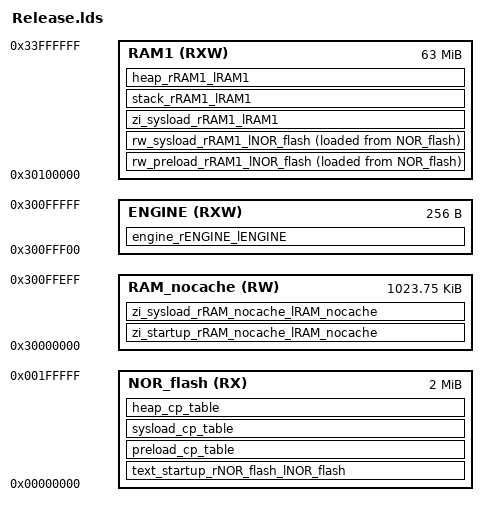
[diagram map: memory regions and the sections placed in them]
/* ld Linker Script - (Debug/Release) */
/* Auto generated by DJYOS lds Editor */
/* Mon Oct 22 22:37:40 CST 2012 */

MEMORY
{
	NOR_flash(RX)		: org = 0, len = 2M
	RAM_nocache(RW)		: org = 0x30000000, len = 0xfff00
	ENGINE(RXW)		: org = 0x300fff00, len = 0x100
	RAM1(RXW)		: org = 0x30100000, len = 63M
}

SECTIONS
{
	
	. = ALIGN(0x08);
	text_startup_rNOR_flash_lNOR_flash :
	{
		KEEP(* (.isr_vector .isr_vector.*))
		./src/bsp/arch/s3c2440/startup/*.o (.text .text.* .rodata .rodata.*)
		./src/bsp/arch/s3c2440/core/*.o (.text .text.* .rodata .rodata.*)
		./src/bsp/arch/arm_common/*.o (.text .text.* .rodata .rodata.*)
		./src/loader/si/pre_loader.o (.text .text.* .rodata .rodata.*)
	}>NOR_flash 
	
	. = ALIGN(0x08);
	zi_startup_rRAM_nocache_lRAM_nocache (NOLOAD) :
	{
		./src/bsp/arch/arm_common/mmucache.o (.mmutable)
	}>RAM_nocache 
	
	. = ALIGN(0x08);
	rw_preload_rRAM1_lNOR_flash :
	{
		KEEP(* (.table.exceptions .table.exceptions.*))
		KEEP(* (.table.vectors .table.vectors.*))
		./src/loader/si/loader.o (.text .text.* .rodata .rodata.*)
		./src/bsp/arch/s3c2440/core/*.o (.text .text.* .rodata .rodata.*)
		./src/djyos/int/int.o (.text .text.* .rodata .rodata.*)
		./src/user/critical/*.o (.text .text.* .rodata .rodata.*)
		./src/bsp/cpu_peripheral/src/gpio.o (.text .text.* .rodata .rodata.*)
		./src/bsp/cpu_peripheral/src/cpu_peri.o (.text .text.* .rodata .rodata.*)
		./src/loader/si/loader.o (.data .data.*)
		./src/bsp/arch/s3c2440/core/*.o  (.data .data.*)
		./src/djyos/int/int.o (.data .data.*)
		./src/user/critical/*.o (.data .data.*)
		./src/bsp/cpu_peripheral/src/gpio.o (.data .data.*)
		./src/bsp/cpu_peripheral/src/cpu_peri.o (.data .data.*)
		./src/loader/si/loader.o (.bss .bss.* COMMON)
		./src/bsp/arch/s3c2440/core/*.o (.bss .bss.* COMMON)
		./src/djyos/int/int.o (.bss .bss.* COMMON)
		./src/user/critical/*.o (.bss .bss.* COMMON)
		./src/bsp/cpu_peripheral/src/gpio.o (.bss .bss.* COMMON)
		./src/bsp/cpu_peripheral/src/cpu_peri.o (.bss .bss.* COMMON)
	}>RAM1 AT>NOR_flash
	
	. = ALIGN(0x08);
	rw_sysload_rRAM1_lNOR_flash :
	{
		* (.text .text.* .rodata .rodata.*)
		* (.data .data.*)
	}>RAM1 AT>NOR_flash
	
	. = ALIGN(0x08);
	zi_sysload_rRAM_nocache_lRAM_nocache (NOLOAD) :
	{
		./src/bsp/board_peripheral/lcd/lcddrv.o(.bss.u8g_video_buffer)
	}>RAM_nocache 
	
	. = ALIGN(0x08);
	zi_sysload_rRAM1_lRAM1 (NOLOAD) :
	{
		* (.bss .bss.* COMMON)
	}>RAM1 
	
	. = ALIGN(0x08);
	preload_cp_table :
	{
		preload_copy_table = .;
		LONG(16)
		LONG(1)
		
		LONG(LOADADDR(rw_preload_rRAM1_lNOR_flash))
		LONG(ADDR(rw_preload_rRAM1_lNOR_flash))
		LONG(SIZEOF(rw_preload_rRAM1_lNOR_flash))
		LONG(1)
	}>NOR_flash 
	
	. = ALIGN(0x08);
	sysload_cp_table :
	{
		sysload_copy_table = .;
		LONG(16)
		LONG(3)
		
		LONG(LOADADDR(rw_sysload_rRAM1_lNOR_flash))
		LONG(ADDR(rw_sysload_rRAM1_lNOR_flash))
		LONG(SIZEOF(rw_sysload_rRAM1_lNOR_flash))
		LONG(1)
		
		LONG(LOADADDR(zi_sysload_rRAM_nocache_lRAM_nocache))
		LONG(ADDR(zi_sysload_rRAM_nocache_lRAM_nocache))
		LONG(SIZEOF(zi_sysload_rRAM_nocache_lRAM_nocache))
		LONG(0)
		
		LONG(LOADADDR(zi_sysload_rRAM1_lRAM1))
		LONG(ADDR(zi_sysload_rRAM1_lRAM1))
		LONG(SIZEOF(zi_sysload_rRAM1_lRAM1))
		LONG(0)
	}>NOR_flash 
	
	. = ALIGN(0x08);
	stack_rRAM1_lRAM1 (NOLOAD) :
	{
		usr_bottom = .;
		KEEP(* (.stack.usr .stack.usr.*))
		usr_top = ALIGN(0x08);
		
		svc_bottom = .;
		KEEP(* (.stack.svc .stack.svc.*))
		svc_top = ALIGN(0x08);
		
		irq_bottom = .;
		KEEP(* (.stack.irq .stack.irq.*))
		irq_top = ALIGN(0x08);
		
		fiq_bottom = .;
		KEEP(* (.stack.fiq .stack.fiq.*))
		fiq_top = ALIGN(0x08);
		
		undef_bottom = .;
		KEEP(* (.stack.undef .stack.undef.*))
		undef_top = ALIGN(0x08);
		
		abort_bottom = .;
		KEEP(* (.stack.abort .stack.abort.*))
		abort_top = ALIGN(0x08);
		
	}>RAM1 
	
	. = ALIGN(0x08);
	heap_rRAM1_lRAM1 (NOLOAD) :
	{
		sys_heap_bottom = .;
	}>RAM1 
	sys_heap_top = 0x30100000+63M;
	
	. = ALIGN(0x08);
	heap_cp_table :
	{
		heap_copy_table = .;
		LONG(12)
		LONG(1)
		
		sys_heap_bottom_cnt = .;
		LONG(sys_heap_bottom)
		sys_heap_top_cnt = .;
		LONG(sys_heap_top)
	}>NOR_flash 
	
	. = ALIGN(0x08);
	engine_rENGINE_lENGINE (NOLOAD) :
	{
		engine_irq = .;
		. += 0x04;
		engine_fiq = .;
		. += 0x04;
		engine_undef = .;
		. += 0x04;
		engine_swi = .;
		. += 0x04;
		engine_pabort = .;
		. += 0x04;
		engine_dabort = .;
		. += 0x04;
		engine_reserved = .;
		. += 0x04;
	}>ENGINE 
}
/**** The End ****/
